AUTOSAR XML (schema 4-0-3)
package /Engine_Composition
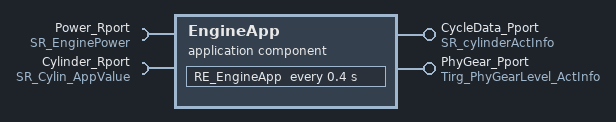
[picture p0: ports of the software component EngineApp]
  application sw component type EngineApp
    require port Power_Rport: required-interface=SR_EnginePower
    require port Cylinder_Rport: required-interface=SR_Cylin_AppValue
    provide port CycleData_Pport: provided-interface=SR_cylinderActInfo
    provide port PhyGear_Pport: provided-interface=Tirg_PhyGearLevel_ActInfo
    behavior IB_EngineApp
      timing event TimingEvent_0: start-on-event=RE_EngineApp, period=0.4
      runnable RE_EngineApp: external-triggering-points=[PhyGear_Pport.level1, PhyGear_Pport.level2, PhyGear_Pport.level3], symbol=RE_EngineApp_func
        data-receive-point-by-values:
          access DRPV_powerValue_0: accessed-variable=Power_Rport.powerValue
          access DRPV_pressure_0: accessed-variable=Cylinder_Rport.pressure
          access DRPV_temperature_0: accessed-variable=Cylinder_Rport.temperature
        data-send-points:
          access DSP_infoArray_0: accessed-variable=CycleData_Pport.infoArray
  sender receiver interface SR_EnginePower
    data powerValue: type=sint16
  sender receiver interface SR_Cylin_AppValue
    data pressure: type=float32
    data temperature: type=float32
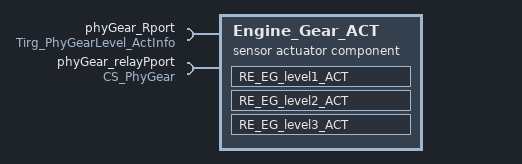
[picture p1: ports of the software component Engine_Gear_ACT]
  sensor actuator sw component type Engine_Gear_ACT
    require port phyGear_Rport: required-interface=Tirg_PhyGearLevel_ActInfo
    require port phyGear_relayPport: required-interface=CS_PhyGear
    behavior IB_Engine_Gear_ACT
      external trigger occurred event ExternalTriggerOccurredEvent_0: start-on-event=RE_EG_level1_ACT, trigger=phyGear_Rport.level1
      external trigger occurred event ExternalTriggerOccurredEvent_1: start-on-event=RE_EG_level2_ACT, trigger=phyGear_Rport.level2
      external trigger occurred event ExternalTriggerOccurredEvent_2: start-on-event=RE_EG_level3_ACT, trigger=phyGear_Rport.level3
      runnable RE_EG_level1_ACT: symbol=RE_EG_level1_ACT_func
        sync call SynchronousServerCallPoint_0: operation=phyGear_relayPport.set_phygear
      runnable RE_EG_level2_ACT: symbol=RE_EG_level2_ACT_func
        sync call SynchronousServerCallPoint_0: operation=phyGear_relayPport.set_phygear
      runnable RE_EG_level3_ACT: symbol=RE_EG_level3_ACT_func
        sync call SynchronousServerCallPoint_0: operation=phyGear_relayPport.set_phygear
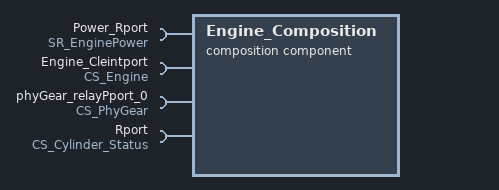
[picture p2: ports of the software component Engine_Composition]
  composition sw component type Engine_Composition
    4 x require port:
      Power_Rport: required-interface=SR_EnginePower
      Engine_Cleintport: required-interface=CS_Engine
      phyGear_relayPport_0: required-interface=CS_PhyGear
      Rport: required-interface=CS_Cylinder_Status
    4 x component:
      CPT_Engine_Cycle_ACT: type=Engine_Cycle_ACT
      CPT_Engine_Gear_ACT: type=Engine_Gear_ACT
      CPT_EngineApp: type=EngineApp
      CPT_Cylinder_Sen: type=Cylinder_Sen
    delegate CPT_EngineApp.Power_Rport <-> outer port Engine_Composition/Power_Rport
    connect CPT_EngineApp.CycleData_Pport -> CPT_Engine_Cycle_ACT.CycleData_Rport
    connect CPT_EngineApp.PhyGear_Pport -> CPT_Engine_Gear_ACT.phyGear_Rport
    delegate CPT_Engine_Cycle_ACT.Engine_Cleintport <-> outer port Engine_Composition/Engine_Cleintport
    delegate CPT_Engine_Gear_ACT.phyGear_relayPport <-> outer port phyGear_relayPport_0
    connect CPT_Cylinder_Sen.Pport -> CPT_EngineApp.Cylinder_Rport
    delegate CPT_Cylinder_Sen.Rport <-> outer port Engine_Composition/Rport
  client server interface CS_PhyGear
    operation set_phygear
      arg gear_value: type=sint8, direction=IN, server-argument-impl-policy=USE-ARGUMENT-TYPE
  client server interface CS_Engine
    operation set_engine
      arg is_on: type=sint8, direction=IN, server-argument-impl-policy=USE-ARGUMENT-TYPE
      arg ignite: type=boolean, direction=IN, server-argument-impl-policy=USE-ARGUMENT-TYPE
      arg fuel_input: type=sint8, direction=IN, server-argument-impl-policy=USE-ARGUMENT-TYPE
  impl type arr_sint8: category=ARRAY
    element ImplementationDataTypeElement_0: array-size=5, array-size-semantics=FIXED-SIZE, implementation-data-type=sint8
  sender receiver interface SR_cylinderActInfo
    data infoArray: type=arr_sint8
  trigger interface Tirg_PhyGearLevel_ActInfo
    trigger level{1..3}
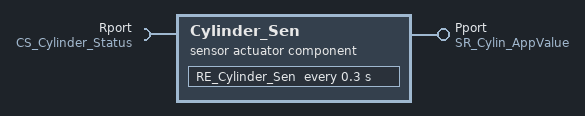
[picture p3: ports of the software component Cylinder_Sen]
  sensor actuator sw component type Cylinder_Sen
    require port Rport: required-interface=CS_Cylinder_Status
    provide port Pport: provided-interface=SR_Cylin_AppValue
    behavior IB_Cylinder_Sen
      timing event TimingEvent_0: start-on-event=RE_Cylinder_Sen, period=0.3
      runnable RE_Cylinder_Sen: symbol=RunnableEntity_0_func
        data-send-points:
          access DSP_pressure_0: accessed-variable=Pport.pressure
          access DSP_temperature_0: accessed-variable=Pport.temperature
        sync call SynchronousServerCallPoint_0: operation=Rport.get_cylinder_Status
  client server interface CS_Cylinder_Status
    operation get_cylinder_Status
      arg temperature: type=sint16, direction=OUT, server-argument-impl-policy=USE-ARGUMENT-TYPE
      arg pressure: type=sint16, direction=OUT, server-argument-impl-policy=USE-ARGUMENT-TYPE
package /Engine_Composition/ARPackage_1
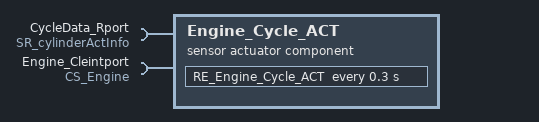
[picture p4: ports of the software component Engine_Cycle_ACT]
  sensor actuator sw component type Engine_Cycle_ACT
    require port CycleData_Rport: required-interface=SR_cylinderActInfo
    require port Engine_Cleintport: required-interface=CS_Engine
    behavior IB_Engine_Cycle_ACT
      timing event TimingEvent_0: start-on-event=RE_Engine_Cycle_ACT, period=0.3
      runnable RE_Engine_Cycle_ACT: symbol=RE_Engine_Cycle_ACT_func
        data-receive-point-by-arguments:
          access DRPA_infoArray_0: accessed-variable=CycleData_Rport.infoArray
        sync call SynchronousServerCallPoint_0: operation=Engine_Cleintport.set_engine
